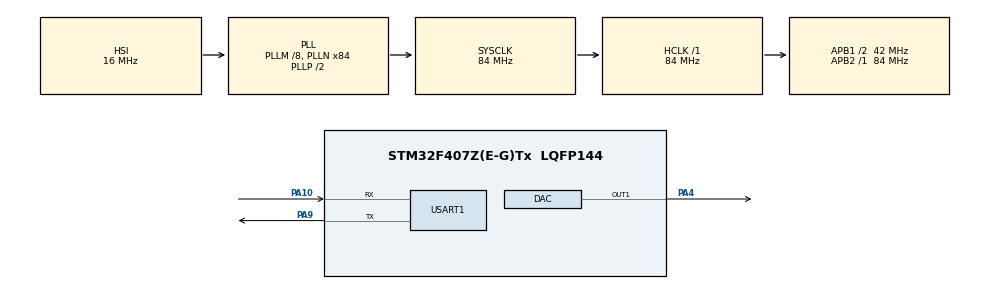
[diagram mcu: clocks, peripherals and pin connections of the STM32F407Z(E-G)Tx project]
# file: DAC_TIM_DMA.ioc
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DAC.DAC_Trigger=DAC_TRIGGER_T6_TRGO
Dma.DAC1.0.Direction=DMA_MEMORY_TO_PERIPH
Dma.DAC1.0.FIFOMode=DMA_FIFOMODE_DISABLE
Dma.DAC1.0.Instance=DMA1_Stream5
Dma.DAC1.0.MemDataAlignment=DMA_MDATAALIGN_HALFWORD
Dma.DAC1.0.MemInc=DMA_MINC_ENABLE
Dma.DAC1.0.Mode=DMA_CIRCULAR
Dma.DAC1.0.PeriphDataAlignment=DMA_PDATAALIGN_HALFWORD
Dma.DAC1.0.PeriphInc=DMA_PINC_DISABLE
Dma.DAC1.0.Priority=DMA_PRIORITY_LOW
Dma.Request0=DAC1
Mcu.Family=STM32F4
Mcu.Name=STM32F407Z(E-G)Tx
Mcu.Package=LQFP144
NVIC.DMA1_Stream5_IRQn=true\:0\:0\:false\:false\:true\:false\:true\:true
NVIC.PriorityGroup=NVIC_PRIORITYGROUP_4
PA10.Mode=Asynchronous
PA10.Signal=USART1_RX
PA13.Mode=Serial_Wire
PA13.Signal=SYS_JTMS-SWDIO
PA14.Mode=Serial_Wire
PA14.Signal=SYS_JTCK-SWCLK
PA4.Signal=COMP_DAC1_group
PA9.Mode=Asynchronous
PA9.Signal=USART1_TX
PC14-OSC32_IN.Mode=LSE-External-Oscillator
PC14-OSC32_IN.Signal=RCC_OSC32_IN
PC15-OSC32_OUT.Mode=LSE-External-Oscillator
PC15-OSC32_OUT.Signal=RCC_OSC32_OUT
PH0-OSC_IN.Mode=HSE-External-Oscillator
PH0-OSC_IN.Signal=RCC_OSC_IN
PH1-OSC_OUT.Mode=HSE-External-Oscillator
PH1-OSC_OUT.Signal=RCC_OSC_OUT
ProjectManager.HeapSize=0x200
ProjectManager.StackSize=0x400
ProjectManager.TargetToolchain=MDK-ARM V5.32
RCC.48MHZClocksFreq_Value=42000000
RCC.AHBFreq_Value=84000000
RCC.APB1CLKDivider=RCC_HCLK_DIV2
RCC.APB1Freq_Value=42000000
RCC.APB1TimFreq_Value=84000000
RCC.APB2Freq_Value=84000000
RCC.APB2TimFreq_Value=84000000
RCC.CortexFreq_Value=84000000
RCC.HCLKFreq_Value=84000000
RCC.HSE_VALUE=25000000
RCC.HSI_VALUE=16000000
RCC.PLLM=8
RCC.PLLN=84
RCC.SYSCLKFreq_VALUE=84000000
RCC.SYSCLKSource=RCC_SYSCLKSOURCE_PLLCLK
RCC.VCOOutputFreq_Value=168000000
SH.COMP_DAC1_group.0=DAC_OUT1,DAC_OUT1
TIM6.AutoReloadPreload=TIM_AUTORELOAD_PRELOAD_ENABLE
TIM6.Period=42 - 1
TIM6.Prescaler=0
TIM6.TIM_MasterOutputTrigger=TIM_TRGO_UPDATE
USART1.VirtualMode=VM_ASYNC
VP_TIM6_VS_ClockSourceINT.Mode=Enable_Timer
board=custom

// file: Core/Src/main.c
/* USER CODE BEGIN Header */
/**
  ******************************************************************************
  * @file           : main.c
  * @brief          : Main program body
  ******************************************************************************
  * @attention
  *
  * Copyright (c) 2024 STMicroelectronics.
  * All rights reserved.
  *
  * This software is licensed under terms that can be found in the LICENSE file
  * in the root directory of this software component.
  * If no LICENSE file comes with this software, it is provided AS-IS.
  *
  ******************************************************************************
  */
/* USER CODE END Header */
#include "main.h"
#include "dac.h"
#include "dma.h"
#include "tim.h"
#include "usart.h"
#include "gpio.h"

/* USER CODE BEGIN Includes */
#include <stdio.h>
/* USER CODE END Includes */

/* USER CODE BEGIN PD */
#define ARRAY_SIZE 10
/* USER CODE END PD */

/* USER CODE BEGIN PM */
int fputc(int ch,FILE *f)
{
    HAL_UART_Transmit(&huart1,(uint8_t *) &ch,1,HAL_MAX_DELAY);
    return ch;
}
int fgetc(FILE *f)
{
    uint8_t ch;
    HAL_UART_Receive(&huart1,(uint8_t *)&ch,1,HAL_MAX_DELAY);
    return ch;
}

const uint16_t SineWave12bit[ARRAY_SIZE]={
		0x0800,
		0x0CB3,
		0x0F9B,
		0x0F9B,
		0x0CB3,
		0x0800,
		0x034D,
		0x0065,
		0x0065,
		0x034D,
};

//const uint16_t SquareWave12bit[ARRAY_SIZE] = {
//    0x0FFF, 0x0FFF, 0x0FFF, 0x0FFF, 0x0FFF, 0x0FFF, 0x0FFF, 0x0FFF, 0x0FFF, 0x0FFF,
//    0x0FFF, 0x0FFF, 0x0FFF, 0x0FFF, 0x0FFF, 0x0FFF, 0x0FFF, 0x0FFF, 0x0FFF, 0x0FFF,
//    0x0FFF, 0x0FFF, 0x0FFF, 0x0FFF, 0x0FFF, 0x0FFF, 0x0FFF, 0x0FFF, 0x0FFF, 0x0FFF,
//    0x0FFF, 0x0FFF, 0x0FFF, 0x0FFF, 0x0FFF, 0x0FFF, 0x0FFF, 0x0FFF, 0x0FFF, 0x0FFF,
//    0x0FFF, 0x0FFF, 0x0FFF, 0x0FFF, 0x0FFF, 0x0FFF, 0x0FFF, 0x0FFF, 0x0FFF, 0x0FFF,
//    0x0000, 0x0000, 0x0000, 0x0000, 0x0000, 0x0000, 0x0000, 0x0000, 0x0000, 0x0000,
//    0x0000, 0x0000, 0x0000, 0x0000, 0x0000, 0x0000, 0x0000, 0x0000, 0x0000, 0x0000,
//    0x0000, 0x0000, 0x0000, 0x0000, 0x0000, 0x0000, 0x0000, 0x0000, 0x0000, 0x0000,
//    0x0000, 0x0000, 0x0000, 0x0000, 0x0000, 0x0000, 0x0000, 0x0000, 0x0000, 0x0000,
//    0x0000, 0x0000, 0x0000, 0x0000, 0x0000, 0x0000, 0x0000, 0x0000, 0x0000, 0x0000,
//};

//const uint16_t TriangleWave12bit[100] = {
//    0x0000, 0x028F, 0x051E, 0x07AE, 0x0A3D, 0x0CCC, 0x0F5B, 0x11EB, 0x147A, 0x1709,
//	  0x1999, 0x1C28, 0x1EB7, 0x2147, 0x23D6, 0x2665, 0x28F5, 0x2B84, 0x2E13, 0x30A3,
//	  0x3332, 0x35C1, 0x3851, 0x3AE0, 0x3D6F, 0x3FFF, 0x3D6F, 0x3AE0, 0x3851, 0x35C1,
//	  0x3332, 0x30A3, 0x2E13, 0x2B84, 0x28F5, 0x2665, 0x23D6, 0x2147, 0x1EB7, 0x1C28,
//	  0x1999, 0x1709, 0x147A, 0x11EB, 0x0F5B, 0x0CCC, 0x0A3D, 0x07AE, 0x051E, 0x028F,
//	  0x0000, 0x028F, 0x051E, 0x07AE, 0x0A3D, 0x0CCC, 0x0F5B, 0x11EB, 0x147A, 0x1709,
//	  0x1999, 0x1C28, 0x1EB7, 0x2147, 0x23D6, 0x2665, 0x28F5, 0x2B84, 0x2E13, 0x30A3,
//	  0x3332, 0x35C1, 0x3851, 0x3AE0, 0x3D6F, 0x3FFF, 0x3D6F, 0x3AE0, 0x3851, 0x35C1,
//	  0x3332, 0x30A3, 0x2E13, 0x2B84, 0x28F5, 0x2665, 0x23D6, 0x2147, 0x1EB7, 0x1C28,
//	  0x1999, 0x1709, 0x147A, 0x11EB, 0x0F5B, 0x0CCC, 0x0A3D, 0x07AE, 0x051E, 0x028F
//};

/* USER CODE END PM */

void SystemClock_Config(void);

/* USER CODE BEGIN 0 */
//void WaveTran(char rece){
//    switch (rece) {
//        case 'S':
//            HAL_DAC_Start_DMA(&hdac, DAC_CHANNEL_1, (uint32_t *)SineWave12bit, 100, DAC_ALIGN_12B_R);
//            break;
//        case 'T':
//            HAL_DAC_Start_DMA(&hdac, DAC_CHANNEL_1, (uint32_t *)TriangleWave12bit, 100, DAC_ALIGN_12B_R);
//            break;
//        case 'M':
//            HAL_DAC_Start_DMA(&hdac, DAC_CHANNEL_1, (uint32_t *)SquareWave12bit, 100, DAC_ALIGN_12B_R);
//            break;
//        default:
//            // 可�?�：处理未知的rece�?
//            break;
//    }
//}
/* USER CODE END 0 */

int main(void)
{

  /* USER CODE BEGIN 1 */
	char rece_data;
	char pre_rece_data;
  /* USER CODE END 1 */

  /* MCU Configuration--------------------------------------------------------*/

  /* Reset of all peripherals, Initializes the Flash interface and the Systick. */
  HAL_Init();

  /* Configure the system clock */
  SystemClock_Config();

  /* Initialize all configured peripherals */
  MX_GPIO_Init();
  MX_DMA_Init();
  MX_DAC_Init();
  MX_TIM6_Init();
  MX_USART1_UART_Init();

  /* Infinite loop */
  /* USER CODE BEGIN WHILE */
	HAL_TIM_Base_Start(&htim6);
  printf("Please enter: M-Square Wave T-Triangle Wave S-Sine Wave \r\n");
	HAL_DAC_Start_DMA(&hdac, DAC_CHANNEL_1, (uint32_t *)SineWave12bit, 10, DAC_ALIGN_12B_R);
  while (1)
  {
//		scanf("%c", &rece_data);
//		if(pre_rece_data != rece_data)HAL_DAC_Stop_DMA(&hdac, DAC_CHANNEL_1);
    /* USER CODE END WHILE */

  }
}

void SystemClock_Config(void)
{
  RCC_OscInitTypeDef RCC_OscInitStruct = {0};
  RCC_ClkInitTypeDef RCC_ClkInitStruct = {0};

  /** Configure the main internal regulator output voltage
  */
  __HAL_RCC_PWR_CLK_ENABLE();
  __HAL_PWR_VOLTAGESCALING_CONFIG(PWR_REGULATOR_VOLTAGE_SCALE1);

  /** Initializes the RCC Oscillators according to the specified parameters
  * in the RCC_OscInitTypeDef structure.
  */
  RCC_OscInitStruct.OscillatorType = RCC_OSCILLATORTYPE_HSI;
  RCC_OscInitStruct.HSIState = RCC_HSI_ON;
  RCC_OscInitStruct.HSICalibrationValue = RCC_HSICALIBRATION_DEFAULT;
  RCC_OscInitStruct.PLL.PLLState = RCC_PLL_ON;
  RCC_OscInitStruct.PLL.PLLSource = RCC_PLLSOURCE_HSI;
  RCC_OscInitStruct.PLL.PLLM = 8;
  RCC_OscInitStruct.PLL.PLLN = 84;
  RCC_OscInitStruct.PLL.PLLP = RCC_PLLP_DIV2;
  RCC_OscInitStruct.PLL.PLLQ = 4;
  if (HAL_RCC_OscConfig(&RCC_OscInitStruct) != HAL_OK)
  {
    Error_Handler();
  }

  /** Initializes the CPU, AHB and APB buses clocks
  */
  RCC_ClkInitStruct.ClockType = RCC_CLOCKTYPE_HCLK|RCC_CLOCKTYPE_SYSCLK
                              |RCC_CLOCKTYPE_PCLK1|RCC_CLOCKTYPE_PCLK2;
  RCC_ClkInitStruct.SYSCLKSource = RCC_SYSCLKSOURCE_PLLCLK;
  RCC_ClkInitStruct.AHBCLKDivider = RCC_SYSCLK_DIV1;
  RCC_ClkInitStruct.APB1CLKDivider = RCC_HCLK_DIV2;
  RCC_ClkInitStruct.APB2CLKDivider = RCC_HCLK_DIV1;

  if (HAL_RCC_ClockConfig(&RCC_ClkInitStruct, FLASH_LATENCY_2) != HAL_OK)
  {
    Error_Handler();
  }
}

void Error_Handler(void)
{
  __disable_irq();
  while (1)
  {
  }
}
